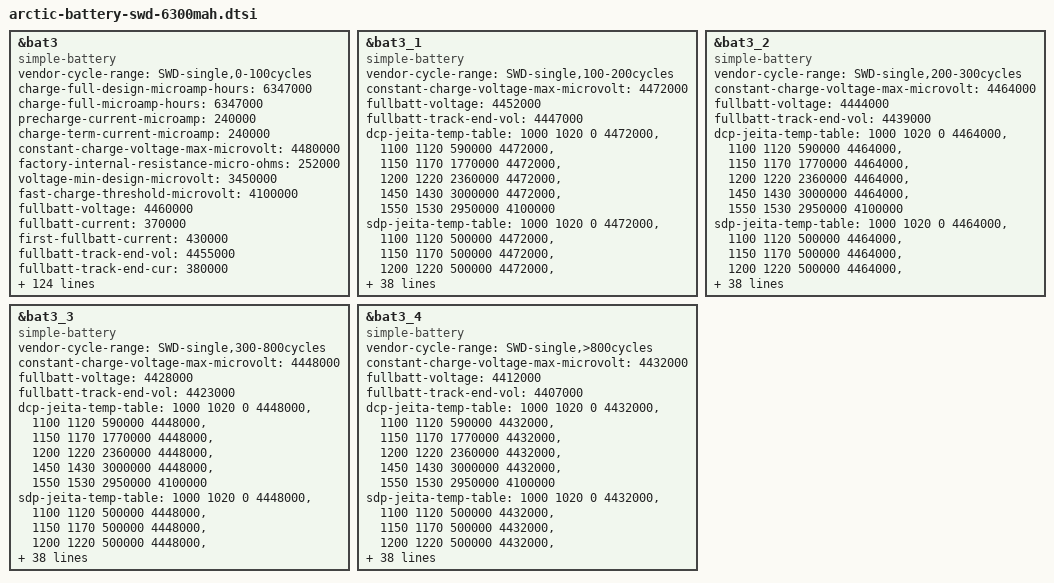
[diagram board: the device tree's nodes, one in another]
/* SWD-single aging 0--100 */
&bat3 {
	compatible = "simple-battery";
	status = "okay";
	vendor-cycle-range = "SWD-single,0-100cycles";
	charge-full-design-microamp-hours = <6347000>;
	charge-full-microamp-hours = <6347000>;
	precharge-current-microamp = <240000>;
	charge-term-current-microamp = <240000>;
	constant-charge-voltage-max-microvolt = <4480000>;
	factory-internal-resistance-micro-ohms = <252000>;
	voltage-min-design-microvolt = <3450000>;

	fast-charge-threshold-microvolt = <4100000>;
	fullbatt-voltage = <4460000>;
	fullbatt-current = <370000>;
	first-fullbatt-current = <430000>;
	fullbatt-track-end-vol = <4455000>;
	fullbatt-track-end-cur = <380000>;
	first-calib-voltage = <3580000>;
	first-calib-capacity = <50>;
	batt-ovp-threshold-microvolt = <4750000>;
	shutdown-voltage = <3150000>; //软件UVLO关机电压

	voltage-temp-table = <1119814 800>, <1007626 850>, <897107 900>,
				<791150 950>, <692012 1000>, <601214 1050>,
				<519546 1100>, <447188 1150>, <383853 1200>,
				<328947 1250>, <281696 1300>, <241249 1350>,
				<206756 1400>, <177412 1450>, <152480 1500>,
				<131307 1550>, <113324 1600>, <98032 1650>;

	temp-advance-fullcap-table = <50 100>, <25 100>, <10 100>, <0 100>,
		<(-10) 100>, <(-20) 100>;

	bcl-vbat-thres-celsius = <(-10)>, <0>, <10>, <25>, <45>;
	bcl-vbat-h-thres-0 = <3500>, <3400>;
	bcl-vbat-l-thres-0 = <3300>, <3200>;
	bcl-vbat-h-thres-1 = <3500>, <3400>;
	bcl-vbat-l-thres-1 = <3300>, <3200>;
	bcl-vbat-h-thres-2 = <3500>, <3400>;
	bcl-vbat-l-thres-2 = <3300>, <3200>;
	bcl-vbat-h-thres-3 = <3500>, <3400>;
	bcl-vbat-l-thres-3 = <3300>, <3200>;
	bcl-vbat-h-thres-4 = <3500>, <3400>;
	bcl-vbat-l-thres-4 = <3300>, <3200>;

	charge-sdp-current-microamp = <500000 500000>;
	charge-dcp-current-microamp = <2940000 1500000>;
	charge-cdp-current-microamp = <900000 900000>;
	charge-unknown-current-microamp = <1000000 1000000>;
	charge-fchg-current-microamp = <3000000 2000000>;
	charge-flash-current-microamp = <4900000 2700000>;
	charge-wl-bpp-current-microamp = <1000000 1000000>;
	charge-wl-epp-current-microamp = <2000000 1000000>;

	cap-calib-energy-density-ocv-table = <3400000 3690000>, <3895000 4480000>;

	dcp-jeita-temp-table = <1000 1020 0 4480000>, <1100 1120 590000 4480000>,
		<1150 1170 1770000 4480000>, <1200 1220 2360000 4480000>,
		<1450 1430 3000000 4480000>, <1550 1530 2950000 4100000>;
	sdp-jeita-temp-table = <1000 1020 0 4480000>, <1100 1120 500000 4480000>,
		<1150 1170 500000 4480000>, <1200 1220 500000 4480000>,
		<1450 1430 500000 4480000>, <1550 1530 500000 4100000>;
	cdp-jeita-temp-table = <1000 1020 0 4480000>, <1100 1120 590000 4480000>,
		<1150 1170 900000 4480000>, <1200 1220 900000 4480000>,
		<1450 1430 900000 4480000>, <1550 1530 900000 4100000>;
	unknown-jeita-temp-table = <1000 1020 0 4480000>, <1100 1120 590000 4480000>,
		<1150 1170 1000000 4480000>, <1200 1220 1000000 4480000>,
		<1450 1430 1000000 4480000>, <1550 1530 1000000 4100000>;
	fchg-jeita-temp-table = <1000 1020 0 4480000>, <1100 1120 590000 4480000>,
		<1150 1170 1770000 4480000>, <1200 1220 2360000 4480000>,
		<1450 1430 3000000 4480000>, <1550 1530 2950000 4100000>;
	flash-jeita-temp-table = <1000 1020 0 4480000>, <1100 1120 590000 4480000>,
		<1150 1170 1770000 4480000>, <1200 1220 2360000 4480000>,
		<1450 1430 3000000 4480000>, <1550 1530 2950000 4100000>;
	wl-bpp-jeita-temp-table = <1000 1020 0 4480000>, <1100 1120 500000 4480000>,
		<1150 1170 500000 4480000>, <1200 1220 500000 4480000>,
		<1450 1430 1000000 4480000>, <1550 1530 500000 4100000>;
	wl-epp-jeita-temp-table = <1000 1020 0 4480000>, <1100 1120 500000 4480000>,
		<1150 1170 500000 4480000>, <1200 1220 500000 4480000>,
		<1450 1430 2000000 4480000>, <1550 1530 500000 4100000>;


	bat-temp = <(-20)>, <(-10)>, <0>, <10>, <25>, <45>;

	/* temp-fcc */
	temp-fcc-fcc = <5788000>, <5974000>, <6199000>, <6269000>, <6347000>, <6284000>;

	/* temp-hc */
	temp-hc-hc = <20>, <20>, <20>, <10>, <10>, <10>;

	/* temp-zero-point-voltage */
	temp-zpvol-zpvol = <3430000>, <3430000>, <3430000>, <3450000>, <3450000>, <3450000>;
	/* temp-abs-zero-point-voltage */
	temp-abs-zpvol-zpvol = <3425000>, <3425000>, <3425000>, <3445000>, <3445000>, <3445000>;
	/* temp-bat-voltage */
	temp-batvol-batvol = <3550000>, <3550000>, <3570000>, <3580000>, <3580000>, <3580000>;

	/* cap-temp-ocv */
	cap-temp-ocv-cap = <100>, <99>, <98>, <97>, <96>, <95>, <94>, <93>, <92>, <91>, <90>,
			<89>, <88>, <87>, <86>, <85>, <84>, <83>, <82>, <81>, <80>,
			<79>, <78>, <77>, <76>, <75>, <74>, <73>, <72>, <71>, <70>,
			<69>, <68>, <67>, <66>, <65>, <64>, <63>, <62>, <61>, <60>,
			<59>, <58>, <57>, <56>, <55>, <54>, <53>, <52>, <51>, <50>,
			<49>, <48>, <47>, <46>, <45>, <44>, <43>, <42>, <41>, <40>,
			<39>, <38>, <37>, <36>, <35>, <34>, <33>, <32>, <31>, <30>,
			<29>, <28>, <27>, <26>, <25>, <24>, <23>, <22>, <21>, <20>,
			<19>, <18>, <17>, <16>, <15>, <14>, <13>, <12>, <11>, <10>,
			<9>, <8>, <7>, <6>, <5>, <4>, <3>, <2>, <1>, <0>;
	cap-temp-ocv-ocv = <
			/* -20 celsius */
			4434000 4406000 4387000 4370000 4354000 4340000 4327000 4313000 4300000 4288000
			4275000 4263000 4251000 4239000 4228000 4216000 4206000 4195000 4185000 4174000
			4164000 4154000 4144000 4133000 4122000 4112000 4102000 4091000 4081000 4070000
			4059000 4048000 4038000 4027000 4016000 4006000 3995000 3985000 3974000 3964000
			3954000 3944000 3934000 3925000 3916000 3906000 3898000 3889000 3881000 3874000
			3866000 3858000 3852000 3845000 3838000 3832000 3826000 3821000 3816000 3810000
			3806000 3802000 3798000 3794000 3790000 3787000 3784000 3780000 3776000 3774000
			3770000 3766000 3762000 3758000 3754000 3750000 3744000 3739000 3734000 3728000
			3721000 3714000 3707000 3699000 3690000 3681000 3671000 3660000 3650000 3638000
			3626000 3613000 3600000 3588000 3576000 3564000 3551000 3535000 3518000 3500000
			3482000
			/* -10 celsius */
			4437000 4414000 4397000 4383000 4369000 4356000 4344000 4332000 4319000 4307000
			4294000 4282000 4270000 4258000 4246000 4234000 4222000 4211000 4200000 4189000
			4179000 4168000 4158000 4148000 4137000 4126000 4116000 4106000 4094000 4084000
			4073000 4062000 4052000 4042000 4031000 4020000 4010000 4000000 3990000 3979000
			3968000 3958000 3947000 3937000 3926000 3916000 3907000 3898000 3889000 3880000
			3872000 3865000 3858000 3851000 3844000 3839000 3833000 3828000 3822000 3818000
			3812000 3808000 3804000 3800000 3796000 3792000 3790000 3788000 3785000 3782000
			3781000 3779000 3776000 3774000 3772000 3770000 3766000 3764000 3760000 3756000
			3752000 3748000 3742000 3734000 3726000 3716000 3703000 3688000 3670000 3650000
			3630000 3610000 3591000 3572000 3554000 3534000 3517000 3501000 3486000 3468000
			3447000
			/* 0 celsius */
			4436000 4416000 4402000 4388000 4374000 4362000 4350000 4338000 4324000 4312000
			4298000 4286000 4272000 4260000 4248000 4235000 4222000 4212000 4200000 4189000
			4178000 4167000 4156000 4145000 4134000 4122000 4112000 4100000 4090000 4080000
			4068000 4058000 4048000 4037000 4027000 4017000 4007000 3998000 3988000 3978000
			3968000 3958000 3948000 3937000 3925000 3914000 3903000 3892000 3883000 3874000
			3866000 3859000 3852000 3846000 3840000 3834000 3829000 3824000 3819000 3814000
			3810000 3806000 3802000 3799000 3796000 3792000 3790000 3787000 3785000 3783000
			3782000 3780000 3778000 3777000 3775000 3774000 3771000 3769000 3766000 3762000
			3758000 3752000 3746000 3739000 3731000 3720000 3705000 3684000 3660000 3634000
			3610000 3587000 3565000 3544000 3528000 3512000 3495000 3478000 3461000 3437000
			3400000
			/* 10 celsius */
			4442000 4420000 4404000 4390000 4376000 4363000 4350000 4337000 4324000 4311000
			4298000 4284000 4272000 4259000 4246000 4234000 4222000 4210000 4198000 4188000
			4177000 4166000 4155000 4144000 4133000 4122000 4111000 4100000 4089000 4078000
			4068000 4058000 4047000 4037000 4028000 4018000 4008000 3998000 3989000 3980000
			3971000 3962000 3952000 3943000 3932000 3920000 3908000 3896000 3886000 3876000
			3868000 3860000 3854000 3848000 3842000 3836000 3831000 3826000 3822000 3818000
			3814000 3810000 3806000 3802000 3799000 3796000 3794000 3790000 3788000 3786000
			3785000 3783000 3782000 3780000 3779000 3777000 3775000 3772000 3770000 3766000
			3762000 3757000 3752000 3748000 3742000 3736000 3727000 3715000 3700000 3680000
			3656000 3627000 3598000 3575000 3558000 3542000 3526000 3509000 3488000 3454000
			3400000
			/* 25 celsius */
			4446000 4426000 4409000 4394000 4380000 4367000 4354000 4341000 4328000 4315000
			4302000 4289000 4276000 4262000 4250000 4238000 4226000 4214000 4202000 4190000
			4180000 4168000 4158000 4146000 4135000 4124000 4113000 4102000 4091000 4080000
			4069000 4058000 4048000 4038000 4028000 4018000 4008000 4000000 3990000 3982000
			3973000 3964000 3955000 3946000 3937000 3926000 3912000 3898000 3886000 3877000
			3869000 3862000 3856000 3850000 3844000 3839000 3834000 3829000 3825000 3820000
			3816000 3813000 3809000 3806000 3803000 3800000 3797000 3795000 3792000 3790000
			3788000 3786000 3785000 3783000 3780000 3776000 3773000 3769000 3766000 3762000
			3758000 3754000 3751000 3748000 3744000 3739000 3732000 3726000 3719000 3711000
			3700000 3688000 3673000 3649000 3621000 3595000 3573000 3551000 3520000 3469000
			3400000
			/* 45 celsius */
			4434000 4414000 4396000 4381000 4366000 4352000 4339000 4326000 4313000 4300000
			4288000 4275000 4262000 4250000 4237000 4225000 4214000 4202000 4191000 4180000
			4169000 4158000 4147000 4136000 4125000 4114000 4103000 4092000 4082000 4071000
			4060000 4050000 4040000 4030000 4021000 4011000 4002000 3993000 3984000 3975000
			3967000 3958000 3950000 3942000 3934000 3924000 3910000 3895000 3884000 3875000
			3868000 3861000 3855000 3849000 3844000 3838000 3833000 3829000 3824000 3820000
			3816000 3812000 3808000 3805000 3801000 3798000 3796000 3793000 3790000 3788000
			3786000 3784000 3782000 3779000 3774000 3767000 3762000 3758000 3754000 3750000
			3746000 3743000 3739000 3736000 3732000 3728000 3721000 3714000 3708000 3700000
			3691000 3682000 3672000 3656000 3632000 3606000 3582000 3557000 3522000 3468000
			3400000
			>;


	/* cap-temp-resist */
	cap-temp-resist-cap = <100>, <99>, <98>, <97>, <96>, <95>, <94>, <93>, <92>, <91>, <90>,
			<89>, <88>, <87>, <86>, <85>, <84>, <83>, <82>, <81>, <80>,
			<79>, <78>, <77>, <76>, <75>, <74>, <73>, <72>, <71>, <70>,
			<69>, <68>, <67>, <66>, <65>, <64>, <63>, <62>, <61>, <60>,
			<59>, <58>, <57>, <56>, <55>, <54>, <53>, <52>, <51>, <50>,
			<49>, <48>, <47>, <46>, <45>, <44>, <43>, <42>, <41>, <40>,
			<39>, <38>, <37>, <36>, <35>, <34>, <33>, <32>, <31>, <30>,
			<29>, <28>, <27>, <26>, <25>, <24>, <23>, <22>, <21>, <20>,
			<19>, <18>, <17>, <16>, <15>, <14>, <13>, <12>, <11>, <10>,
			<9>, <8>, <7>, <6>, <5>, <4>, <3>, <2>, <1>, <0>;
	cap-temp-resist-resist = <
		  /* -20 celsius m o */
			822  822  817  814  810  804  798  790  782  773
			767  760  756  750  742  738  732  724  720  716
			712  704  702  700  696  694  698  694  690  688
			688  690  684  686  684  680  680  678  676  674
			676  674  671  672  672  668  666  668  671  671
			671  670  670  676  679  674  680  682  680  686
			690  696  696  700  707  714  724  730  738  746
			754  763  772  783  798  810  820  833  844  856
			871  879  894  912  930  950  966  994 1033 1080
			1149 1262 1442 1784 2441 2666 2666 2666 2666 2666
			2666
		  /* -10 celsius */
			416  416  424  425  427  428  427  423  420  417
			412  408  402  398  394  389  386  382  380  377
			374  374  372  372  372  372  373  372  374  372
			374  374  374  374  374  374  373  372  370  370
			368  366  362  360  357  354  352  349  347  346
			344  342  342  342  343  345  346  347  348  349
			350  351  352  354  356  358  360  362  366  369
			372  376  381  386  392  398  406  414  422  432
			442  453  466  479  493  506  520  531  542  553
			570  600  658  789 1196 2203 2552 2552 2552 2552
			2552
		  /* 0 celsius */
			216  216  216  214  213  212  210  208  206  204
			202  200  199  198  197  196  194  194  193  193
			192  192  192  192  193  194  194  195  196  198
			198  200  201  202  203  204  206  208  209  209
			210  209  208  204  200  195  190  186  183  181
			178  178  178  178  178  178  179  179  180  180
			180  182  182  184  184  184  186  187  188  188
			190  192  194  197  199  201  203  206  208  212
			214  217  222  229  238  250  260  268  267  264
			264  268  276  294  336  479 1255 2456 2456 2456
			2456
		  /* 10 celsius */
			160 160 160 158 156 156 154 153 152 150
			148 146 146 144 143 142 140 140 138 138
			138 138 138 138 138 139 139 139 140 141
			142 142 144 144 146 147 148 150 152 153
			155 156 157 158 156 152 146 140 136 132
			130 130 130 129 129 128 128 130 130 130
			130 130 131 132 132 131 132 134 134 134
			136 136 137 137 138 138 138 138 138 138
			137 138 138 140 142 146 150 156 164 173
			176 172 166 166 168 173 185 210 286 654
			1744
		  /* 25 celsius */
			105 105 104 104 103 102 102 102 102 102
			100 100 100 100 100 100 100  99 100 100
			100 100 101 102 100 101 102 102 102 102
			104 104 106 106 107 108 108 110 111 112
			114 116 118 119 120 118 112 106 102 100
			100  98  98  98  98  98  98  98  98  98
			98   98  99 100 100 101 102 103 103 104
			104 104 105 106 104 102 100 100 100 100
			100 100 100 102 102 104 103 104 105 107
			110 114 118 118 119 119 118 119 120 120
			125
		  /* 45 celsius */
			90  90  90  89  89  90  89  89  89  89
			89  90  89  90  89  90  90  90  90  90
			90  90  91  91  90  92  92  92  92  92
			92  92  94  94  94  95  95  96  96  98
			98 100 102 103 106 105 100  93  91  90
			90  90  90  89  90  89  90  90  90  90
			90  91  90  91  92  92  91  92  93  94
			95  96  96  96  92  89  89  90  91  91
			91  92  92  92  94  94  92  92  94  96
			96  98  99 101 102 103 103 104 102 102
			105
		>;
	cap-temp-resist-cycle = <300>, <600>;
	cap-temp-resist-ratio-0 = <
		  /* -20 celsius m o */
		  1030 1030 1030 1030 1030 1030 1030 1030 1030 1030 1040
		  1050 1050 1050 1060 1060 1060 1060 1060 1060 1060 1060
		  1060 1060 1060 1060 1060 1060 1060 1060 1060 1060 1060
		  1060 1060 1060 1060 1060 1060 1060 1060 1060 1060 1060
		  1060 1060 1060 1060 1060 1060 1060 1060 1060 1060 1060
		  1060 1060 1060 1060 1060 1060 1060 1060 1060 1050 1050
		  1050 1050 1050 1050 1050 1050 1050 1050 1050 1050 1050
		  1050 1050 1050 1050 1050 1050 1050 1050 1050 1050 1050
		  1050 1050 1050 1050 1050 1050 1050 1050 1050 1050 1050
		  1050 1050
		  /* -10 celsius */
		  1050 1050 1050 1050 1050 1050 1050 1050 1050 1050 1050
		  1050 1050 1050 1050 1050 1050 1050 1050 1050 1050 1050
		  1050 1050 1050 1050 1050 1050 1050 1050 1050 1050 1050
		  1050 1050 1050 1050 1050 1050 1050 1050 1050 1050 1050
		  1050 1050 1050 1050 1050 1050 1050 1050 1050 1050 1050
		  1050 1050 1050 1050 1050 1050 1050 1050 1050 1050 1050
		  1050 1050 1050 1050 1050 1050 1050 1050 1050 1050 1050
		  1050 1050 1050 1050 1050 1050 1050 1050 1050 1050 1050
		  1050 1050 1050 1050 1050 1050 1050 1050 1050 1050 1050
		  1050 1050
		  /* 0 celsius */
		  1160 1160 1160 1160 1160 1160 1160 1160 1170 1170 1170
		  1170 1170 1170 1170 1170 1170 1170 1170 1170 1170 1170
		  1170 1170 1170 1170 1170 1170 1170 1170 1170 1170 1170
		  1170 1170 1170 1180 1180 1180 1180 1180 1180 1180 1180
		  1180 1180 1190 1190 1190 1190 1190 1190 1190 1190 1190
		  1190 1190 1190 1190 1190 1190 1190 1190 1190 1190 1190
		  1190 1200 1200 1210 1220 1220 1220 1220 1220 1220 1230
		  1230 1230 1230 1230 1230 1230 1230 1230 1230 1230 1230
		  1230 1230 1230 1230 1250 1270 1290 1320 1350 1370 1400
		  1430 1430
		  /* 10 celsius */
		  1270 1270 1270 1270 1270 1270 1270 1270 1270 1280 1280
		  1280 1280 1290 1290 1290 1290 1290 1290 1290 1290 1290
		  1290 1300 1300 1300 1300 1300 1300 1300 1300 1300 1300
		  1300 1310 1310 1310 1310 1310 1310 1310 1310 1310 1310
		  1320 1320 1320 1320 1320 1320 1320 1320 1320 1320 1320
		  1320 1320 1330 1330 1330 1330 1330 1330 1330 1330 1330
		  1330 1330 1330 1330 1340 1340 1340 1340 1340 1340 1350
		  1360 1380 1400 1410 1430 1450 1470 1490 1500 1510 1520
		  1530 1530 1530 1530 1530 1530 1530 1530 1530 1530 1530
		  1530 1530
		  /* 25 celsius */
		  1110 1110 1110 1110 1110 1110 1110 1120 1120 1120 1130
		  1130 1140 1140 1140 1140 1140 1130 1130 1130 1130 1130
		  1130 1120 1120 1120 1120 1120 1120 1120 1120 1120 1120
		  1130 1130 1130 1130 1130 1140 1140 1140 1140 1140 1150
		  1150 1160 1160 1160 1160 1160 1160 1160 1160 1150 1150
		  1150 1150 1150 1160 1160 1160 1160 1160 1160 1150 1150
		  1150 1150 1150 1160 1160 1160 1160 1160 1160 1160 1160
		  1160 1160 1160 1160 1160 1160 1160 1160 1160 1150 1150
		  1150 1150 1150 1150 1150 1160 1160 1160 1160 1160 1160
		  1160 1160
		  /* 45 celsius */
		  1260 1260 1260 1260 1260 1260 1260 1270 1280 1290 1300
		  1300 1300 1300 1300 1300 1300 1300 1300 1300 1300 1300
		  1290 1290 1280 1270 1280 1290 1300 1310 1310 1310 1310
		  1310 1310 1310 1310 1310 1310 1310 1310 1310 1300 1290
		  1280 1270 1270 1270 1270 1270 1290 1290 1290 1290 1300
		  1310 1310 1310 1310 1310 1310 1310 1310 1300 1290 1290
		  1290 1290 1290 1300 1310 1310 1320 1320 1320 1320 1320
		  1320 1320 1320 1320 1320 1320 1320 1320 1320 1320 1310
		  1310 1310 1310 1310 1310 1310 1310 1320 1320 1320 1320
		  1320 1320
		>;

	cap-temp-resist-ratio-1 = <
		  /* -20 celsius m o */
		  1160 1160 1160 1160 1160 1160 1160 1160 1160 1170 1170
		  1180 1180 1190 1190 1190 1190 1200 1200 1210 1210 1210
		  1220 1220 1230 1230 1240 1250 1260 1270 1270 1270 1280
		  1290 1300 1310 1320 1340 1360 1380 1400 1400 1430 1460
		  1490 1520 1520 1520 1550 1590 1630 1660 1660 1690 1720
		  1750 1770 1770 1770 1770 1770 1770 1770 1770 1770 1770
		  1770 1770 1770 1770 1770 1770 1770 1770 1770 1770 1770
		  1770 1770 1770 1770 1770 1770 1770 1770 1770 1770 1770
		  1770 1770 1770 1770 1770 1770 1770 1770 1770 1770 1770
		  1770 1770
		  /* -10 celsius */
		  1180 1180 1180 1180 1180 1180 1180 1180 1170 1170 1170
		  1170 1170 1170 1170 1170 1170 1170 1170 1170 1170 1170
		  1170 1170 1170 1170 1170 1170 1170 1170 1170 1170 1170
		  1170 1170 1170 1170 1170 1170 1170 1170 1170 1170 1190
		  1190 1190 1190 1190 1200 1200 1200 1200 1200 1210 1210
		  1210 1210 1210 1210 1220 1240 1250 1270 1290 1290 1290
		  1290 1290 1290 1290 1300 1310 1320 1330 1340 1350 1350
		  1350 1370 1390 1410 1420 1440 1440 1460 1480 1500 1530
		  1550 1570 1590 1610 1620 1620 1620 1620 1620 1620 1620
		  1620 1620
		  /* 0 celsius */
		  1420 1420 1420 1420 1420 1420 1420 1420 1410 1410 1410
		  1410 1410 1410 1410 1410 1410 1410 1410 1410 1410 1410
		  1400 1400 1400 1400 1400 1400 1400 1400 1400 1400 1400
		  1400 1400 1400 1400 1400 1400 1400 1400 1400 1410 1410
		  1410 1410 1420 1420 1420 1420 1420 1420 1420 1420 1420
		  1420 1430 1430 1430 1430 1430 1430 1450 1450 1450 1450
		  1450 1450 1500 1500 1500 1500 1500 1500 1530 1530 1530
		  1530 1530 1530 1550 1550 1550 1550 1610 1610 1610 1610
		  1650 1700 1750 1800 1850 1900 1900 1900 1900 1900 1900
		  1900 1900
		  /* 10 celsius */
		  1400 1400 1400 1400 1400 1400 1400 1400 1400 1420 1420
		  1420 1420 1420 1420 1420 1420 1420 1420 1420 1420 1420
		  1420 1420 1420 1420 1420 1420 1410 1410 1410 1410 1410
		  1410 1410 1410 1410 1410 1410 1410 1410 1410 1410 1410
		  1410 1420 1420 1420 1420 1430 1430 1430 1430 1430 1420
		  1430 1430 1430 1430 1430 1430 1430 1430 1430 1430 1430
		  1430 1430 1430 1430 1470 1470 1470 1470 1470 1530 1530
		  1530 1530 1530 1590 1590 1590 1590 1630 1680 1710 1710
		  1780 1840 1900 1950 2000 2050 2100 2150 2200 2250 2250
		  2250 2250
		  /* 25 celsius */
		  1320 1320 1320 1320 1320 1320 1320 1320 1320 1320 1320
		  1320 1310 1310 1310 1310 1310 1310 1300 1300 1300 1300
		  1300 1290 1290 1290 1290 1290 1280 1280 1280 1280 1280
		  1280 1280 1280 1280 1280 1280 1280 1280 1280 1280 1290
		  1290 1300 1310 1310 1310 1310 1310 1310 1310 1310 1310
		  1310 1310 1310 1310 1310 1310 1310 1310 1310 1310 1310
		  1310 1310 1310 1310 1310 1310 1310 1320 1330 1340 1350
		  1350 1360 1360 1360 1360 1360 1370 1370 1370 1380 1390
		  1400 1410 1420 1430 1450 1460 1460 1460 1460 1460 1460
		  1460 1460
		  /* 45 celsius */
		  1298 1298 1298 1298 1298 1298 1298 1308 1318 1329 1339
		  1339 1339 1339 1339 1339 1339 1339 1339 1339 1339 1339
		  1329 1329 1318 1308 1318 1329 1339 1349 1349 1349 1349
		  1349 1349 1349 1349 1349 1349 1349 1349 1349 1339 1329
		  1318 1308 1308 1308 1308 1308 1329 1329 1329 1329 1339
		  1349 1349 1349 1349 1349 1349 1349 1349 1339 1329 1329
		  1329 1329 1329 1339 1349 1349 1360 1360 1360 1360 1360
		  1360 1360 1360 1360 1360 1360 1360 1360 1360 1360 1349
		  1349 1349 1349 1349 1349 1349 1349 1360 1360 1360 1360
		  1360 1360
		>;
};

/* SWD-single aging 100--200 */
&bat3_1 {
	compatible = "simple-battery";
	status = "okay";
	vendor-cycle-range = "SWD-single,100-200cycles";
	constant-charge-voltage-max-microvolt = <4472000>;
	fullbatt-voltage = <4452000>;
	fullbatt-track-end-vol = <4447000>;

	dcp-jeita-temp-table = <1000 1020 0 4472000>, <1100 1120 590000 4472000>,
		<1150 1170 1770000 4472000>, <1200 1220 2360000 4472000>,
		<1450 1430 3000000 4472000>, <1550 1530 2950000 4100000>;
	sdp-jeita-temp-table = <1000 1020 0 4472000>, <1100 1120 500000 4472000>,
		<1150 1170 500000 4472000>, <1200 1220 500000 4472000>,
		<1450 1430 500000 4472000>, <1550 1530 500000 4100000>;
	cdp-jeita-temp-table = <1000 1020 0 4472000>, <1100 1120 590000 4472000>,
		<1150 1170 900000 4472000>, <1200 1220 900000 4472000>,
		<1450 1430 900000 4472000>, <1550 1530 900000 4100000>;
	unknown-jeita-temp-table = <1000 1020 0 4472000>, <1100 1120 590000 4472000>,
		<1150 1170 1000000 4472000>, <1200 1220 1000000 4472000>,
		<1450 1430 1000000 4472000>, <1550 1530 1000000 4100000>;
	fchg-jeita-temp-table = <1000 1020 0 4472000>, <1100 1120 590000 4472000>,
		<1150 1170 1770000 4472000>, <1200 1220 2360000 4472000>,
		<1450 1430 3000000 4472000>, <1550 1530 2950000 4100000>;
	flash-jeita-temp-table = <1000 1020 0 4472000>, <1100 1120 590000 4472000>,
		<1150 1170 1770000 4472000>, <1200 1220 2360000 4472000>,
		<1450 1430 3000000 4472000>, <1550 1530 2950000 4100000>;
	wl-bpp-jeita-temp-table = <1000 1020 0 4472000>, <1100 1120 500000 4472000>,
		<1150 1170 500000 4472000>, <1200 1220 500000 4472000>,
		<1450 1430 1000000 4472000>, <1550 1530 500000 4100000>;
	wl-epp-jeita-temp-table = <1000 1020 0 4472000>, <1100 1120 500000 4472000>,
		<1150 1170 500000 4472000>, <1200 1220 500000 4472000>,
		<1450 1430 2000000 4472000>, <1550 1530 500000 4100000>;
};

/* SWD-single aging 200--300 */
&bat3_2 {
	compatible = "simple-battery";
	status = "okay";
	vendor-cycle-range = "SWD-single,200-300cycles";
	constant-charge-voltage-max-microvolt = <4464000>;
	fullbatt-voltage = <4444000>;
	fullbatt-track-end-vol = <4439000>;

	dcp-jeita-temp-table = <1000 1020 0 4464000>, <1100 1120 590000 4464000>,
		<1150 1170 1770000 4464000>, <1200 1220 2360000 4464000>,
		<1450 1430 3000000 4464000>, <1550 1530 2950000 4100000>;
	sdp-jeita-temp-table = <1000 1020 0 4464000>, <1100 1120 500000 4464000>,
		<1150 1170 500000 4464000>, <1200 1220 500000 4464000>,
		<1450 1430 500000 4464000>, <1550 1530 500000 4100000>;
	cdp-jeita-temp-table = <1000 1020 0 4464000>, <1100 1120 590000 4464000>,
		<1150 1170 900000 4464000>, <1200 1220 900000 4464000>,
		<1450 1430 900000 4464000>, <1550 1530 900000 4100000>;
	unknown-jeita-temp-table = <1000 1020 0 4464000>, <1100 1120 590000 4464000>,
		<1150 1170 1000000 4464000>, <1200 1220 1000000 4464000>,
		<1450 1430 1000000 4464000>, <1550 1530 1000000 4100000>;
	fchg-jeita-temp-table = <1000 1020 0 4464000>, <1100 1120 590000 4464000>,
		<1150 1170 1770000 4464000>, <1200 1220 2360000 4464000>,
		<1450 1430 3000000 4464000>, <1550 1530 2950000 4100000>;
	flash-jeita-temp-table = <1000 1020 0 4464000>, <1100 1120 590000 4464000>,
		<1150 1170 1770000 4464000>, <1200 1220 2360000 4464000>,
		<1450 1430 3000000 4464000>, <1550 1530 2950000 4100000>;
	wl-bpp-jeita-temp-table = <1000 1020 0 4464000>, <1100 1120 500000 4464000>,
		<1150 1170 500000 4464000>, <1200 1220 500000 4464000>,
		<1450 1430 1000000 4464000>, <1550 1530 500000 4100000>;
	wl-epp-jeita-temp-table = <1000 1020 0 4464000>, <1100 1120 500000 4464000>,
		<1150 1170 500000 4464000>, <1200 1220 500000 4464000>,
		<1450 1430 2000000 4464000>, <1550 1530 500000 4100000>;
};

/* SWD-single aging 300--800 */
&bat3_3 {
	compatible = "simple-battery";
	status = "okay";
	vendor-cycle-range = "SWD-single,300-800cycles";
	constant-charge-voltage-max-microvolt = <4448000>;
	fullbatt-voltage = <4428000>;
	fullbatt-track-end-vol = <4423000>;

	dcp-jeita-temp-table = <1000 1020 0 4448000>, <1100 1120 590000 4448000>,
		<1150 1170 1770000 4448000>, <1200 1220 2360000 4448000>,
		<1450 1430 3000000 4448000>, <1550 1530 2950000 4100000>;
	sdp-jeita-temp-table = <1000 1020 0 4448000>, <1100 1120 500000 4448000>,
		<1150 1170 500000 4448000>, <1200 1220 500000 4448000>,
		<1450 1430 500000 4448000>, <1550 1530 500000 4100000>;
	cdp-jeita-temp-table = <1000 1020 0 4448000>, <1100 1120 590000 4448000>,
		<1150 1170 900000 4448000>, <1200 1220 900000 4448000>,
		<1450 1430 900000 4448000>, <1550 1530 900000 4100000>;
	unknown-jeita-temp-table = <1000 1020 0 4448000>, <1100 1120 590000 4448000>,
		<1150 1170 1000000 4448000>, <1200 1220 1000000 4448000>,
		<1450 1430 1000000 4448000>, <1550 1530 1000000 4100000>;
	fchg-jeita-temp-table = <1000 1020 0 4448000>, <1100 1120 590000 4448000>,
		<1150 1170 1770000 4448000>, <1200 1220 2360000 4448000>,
		<1450 1430 3000000 4448000>, <1550 1530 2950000 4100000>;
	flash-jeita-temp-table = <1000 1020 0 4448000>, <1100 1120 590000 4448000>,
		<1150 1170 1770000 4448000>, <1200 1220 2360000 4448000>,
		<1450 1430 3000000 4448000>, <1550 1530 2950000 4100000>;
	wl-bpp-jeita-temp-table = <1000 1020 0 4448000>, <1100 1120 500000 4448000>,
		<1150 1170 500000 4448000>, <1200 1220 500000 4448000>,
		<1450 1430 1000000 4448000>, <1550 1530 500000 4100000>;
	wl-epp-jeita-temp-table = <1000 1020 0 4448000>, <1100 1120 500000 4448000>,
		<1150 1170 500000 4448000>, <1200 1220 500000 4448000>,
		<1450 1430 2000000 4448000>, <1550 1530 500000 4100000>;
};

/* SWD-single aging > 800 */
&bat3_4 {
	compatible = "simple-battery";
	status = "okay";
	vendor-cycle-range = "SWD-single,>800cycles";
	constant-charge-voltage-max-microvolt = <4432000>;
	fullbatt-voltage = <4412000>;
	fullbatt-track-end-vol = <4407000>;

	dcp-jeita-temp-table = <1000 1020 0 4432000>, <1100 1120 590000 4432000>,
		<1150 1170 1770000 4432000>, <1200 1220 2360000 4432000>,
		<1450 1430 3000000 4432000>, <1550 1530 2950000 4100000>;
	sdp-jeita-temp-table = <1000 1020 0 4432000>, <1100 1120 500000 4432000>,
		<1150 1170 500000 4432000>, <1200 1220 500000 4432000>,
		<1450 1430 500000 4432000>, <1550 1530 500000 4100000>;
	cdp-jeita-temp-table = <1000 1020 0 4432000>, <1100 1120 590000 4432000>,
		<1150 1170 900000 4432000>, <1200 1220 900000 4432000>,
		<1450 1430 900000 4432000>, <1550 1530 900000 4100000>;
	unknown-jeita-temp-table = <1000 1020 0 4432000>, <1100 1120 590000 4432000>,
		<1150 1170 1000000 4432000>, <1200 1220 1000000 4432000>,
		<1450 1430 1000000 4432000>, <1550 1530 1000000 4100000>;
	fchg-jeita-temp-table = <1000 1020 0 4432000>, <1100 1120 590000 4432000>,
		<1150 1170 1770000 4432000>, <1200 1220 2360000 4432000>,
		<1450 1430 3000000 4432000>, <1550 1530 2950000 4100000>;
	flash-jeita-temp-table = <1000 1020 0 4432000>, <1100 1120 590000 4432000>,
		<1150 1170 1770000 4432000>, <1200 1220 2360000 4432000>,
		<1450 1430 3000000 4432000>, <1550 1530 2950000 4100000>;
	wl-bpp-jeita-temp-table = <1000 1020 0 4432000>, <1100 1120 500000 4432000>,
		<1150 1170 500000 4432000>, <1200 1220 500000 4432000>,
		<1450 1430 1000000 4432000>, <1550 1530 500000 4100000>;
	wl-epp-jeita-temp-table = <1000 1020 0 4432000>, <1100 1120 500000 4432000>,
		<1150 1170 500000 4432000>, <1200 1220 500000 4432000>,
		<1450 1430 2000000 4432000>, <1550 1530 500000 4100000>;
};
